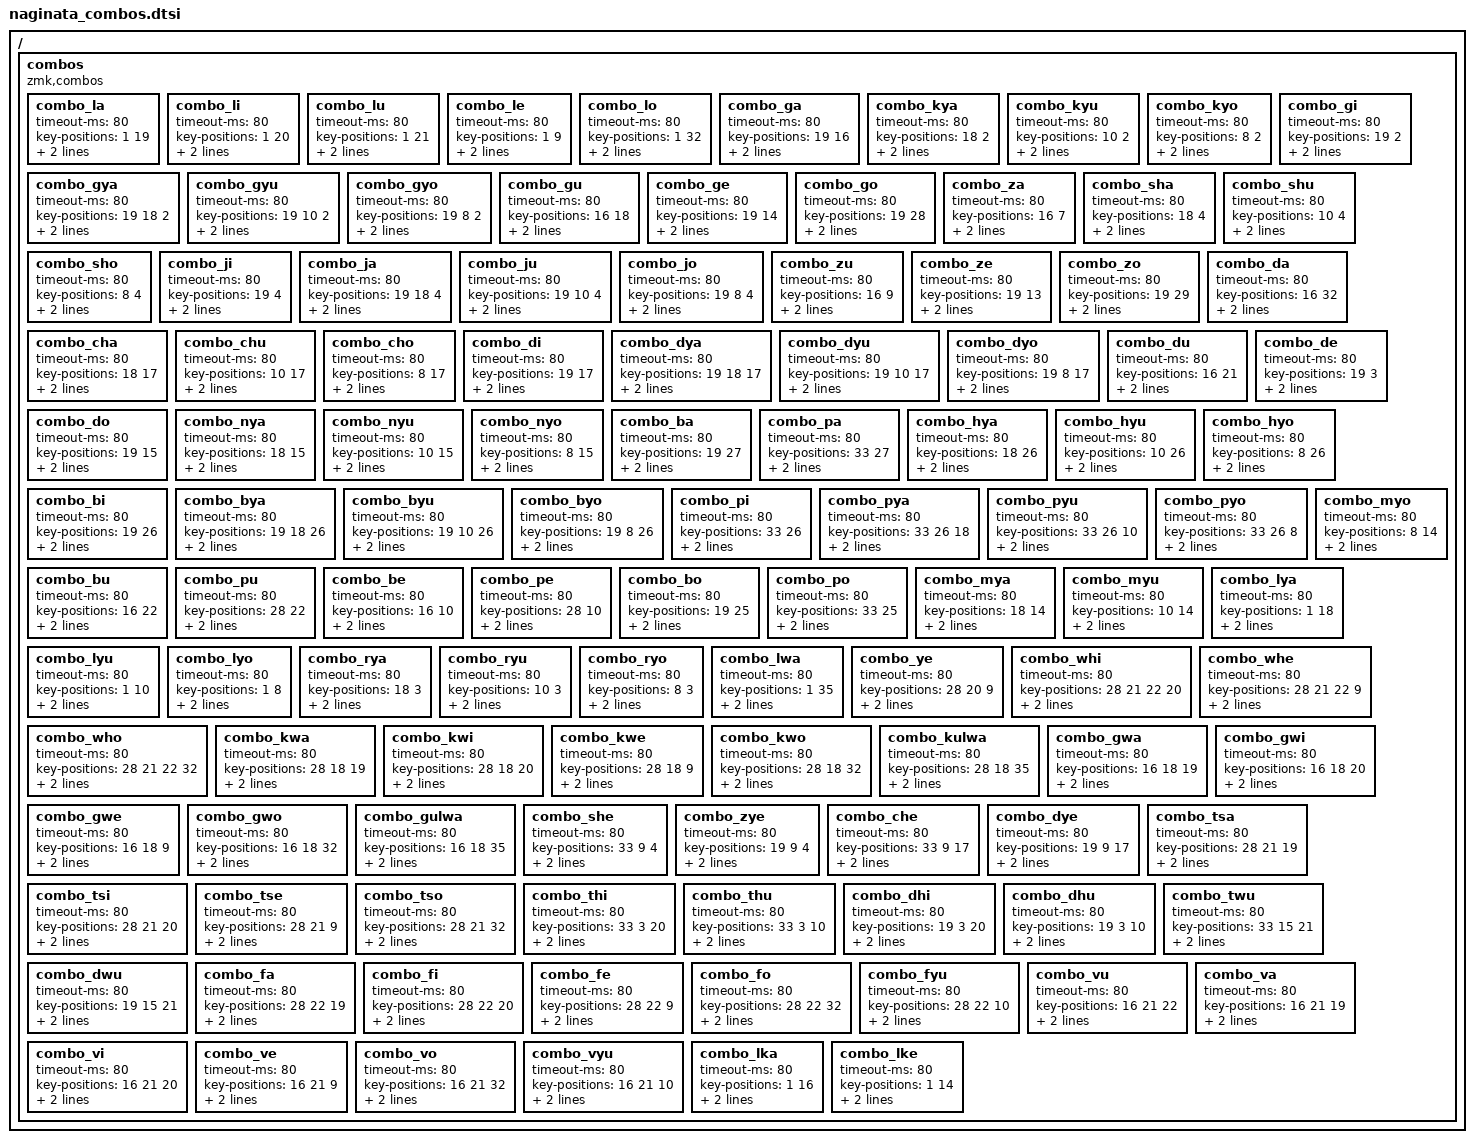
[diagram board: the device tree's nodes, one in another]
/*
 * Copyright (c) 2020 The ZMK Contributors
 *
 * SPDX-License-Identifier: MIT
 */

#pragma once

#include "layers.h"

/ {
    combos {
        compatible = "zmk,combos";

        combo_la { // ぁ
            timeout-ms = <80>;
            key-positions = <1 19>;
            bindings = <&kana_la>;
            layers = <LAYER_NAGINATA LAYER_NAGINATA_EXT>;
        };

        combo_li { // ぃ
            timeout-ms = <80>;
            key-positions = <1 20>;
            bindings = <&kana_li>;
            layers = <LAYER_NAGINATA LAYER_NAGINATA_EXT>;
        };

        combo_lu { // ぅ
            timeout-ms = <80>;
            key-positions = <1 21>;
            bindings = <&kana_lu>;
            layers = <LAYER_NAGINATA LAYER_NAGINATA_EXT>;
        };

        combo_le { // ぇ
            timeout-ms = <80>;
            key-positions = <1 9>;
            bindings = <&kana_le>;
            layers = <LAYER_NAGINATA LAYER_NAGINATA_EXT>;
        };

        combo_lo { // ぉ
            timeout-ms = <80>;
            key-positions = <1 32>;
            bindings = <&kana_lo>;
            layers = <LAYER_NAGINATA LAYER_NAGINATA_EXT>;
        };

        combo_ga { // が
            timeout-ms = <80>;
            key-positions = <19 16>;
            bindings = <&kana_ga>;
            layers = <LAYER_NAGINATA LAYER_NAGINATA_EXT>;
        };

        combo_kya { // きゃ
            timeout-ms = <80>;
            key-positions = <18 2>;
            bindings = <&kana_kya>;
            layers = <LAYER_NAGINATA LAYER_NAGINATA_EXT>;
        };

        combo_kyu { // きゅ
            timeout-ms = <80>;
            key-positions = <10 2>;
            bindings = <&kana_kyu>;
            layers = <LAYER_NAGINATA LAYER_NAGINATA_EXT>;
        };

        combo_kyo { // きょ
            timeout-ms = <80>;
            key-positions = <8 2>;
            bindings = <&kana_kyo>;
            layers = <LAYER_NAGINATA LAYER_NAGINATA_EXT>;
        };

        combo_gi { // ぎ
            timeout-ms = <80>;
            key-positions = <19 2>;
            bindings = <&kana_gi>;
            layers = <LAYER_NAGINATA LAYER_NAGINATA_EXT>;
        };

        combo_gya { // ぎゃ
            timeout-ms = <80>;
            key-positions = <19 18 2>;
            bindings = <&kana_gya>;
            layers = <LAYER_NAGINATA LAYER_NAGINATA_EXT>;
        };

        combo_gyu { // ぎゅ
            timeout-ms = <80>;
            key-positions = <19 10 2>;
            bindings = <&kana_gyu>;
            layers = <LAYER_NAGINATA LAYER_NAGINATA_EXT>;
        };

        combo_gyo { // ぎょ
            timeout-ms = <80>;
            key-positions = <19 8 2>;
            bindings = <&kana_gyo>;
            layers = <LAYER_NAGINATA LAYER_NAGINATA_EXT>;
        };

        combo_gu { // ぐ
            timeout-ms = <80>;
            key-positions = <16 18>;
            bindings = <&kana_gu>;
            layers = <LAYER_NAGINATA LAYER_NAGINATA_EXT>;
        };

        combo_ge { // げ
            timeout-ms = <80>;
            key-positions = <19 14>;
            bindings = <&kana_ge>;
            layers = <LAYER_NAGINATA LAYER_NAGINATA_EXT>;
        };

        combo_go { // ご
            timeout-ms = <80>;
            key-positions = <19 28>;
            bindings = <&kana_go>;
            layers = <LAYER_NAGINATA LAYER_NAGINATA_EXT>;
        };

        combo_za { // ざ
            timeout-ms = <80>;
            key-positions = <16 7>;
            bindings = <&kana_za>;
            layers = <LAYER_NAGINATA LAYER_NAGINATA_EXT>;
        };

        combo_sha { // しゃ
            timeout-ms = <80>;
            key-positions = <18 4>;
            bindings = <&kana_sha>;
            layers = <LAYER_NAGINATA LAYER_NAGINATA_EXT>;
        };

        combo_shu { // しゅ
            timeout-ms = <80>;
            key-positions = <10 4>;
            bindings = <&kana_shu>;
            layers = <LAYER_NAGINATA LAYER_NAGINATA_EXT>;
        };

        combo_sho { // しょ
            timeout-ms = <80>;
            key-positions = <8 4>;
            bindings = <&kana_sho>;
            layers = <LAYER_NAGINATA LAYER_NAGINATA_EXT>;
        };

        combo_ji { // じ
            timeout-ms = <80>;
            key-positions = <19 4>;
            bindings = <&kana_ji>;
            layers = <LAYER_NAGINATA LAYER_NAGINATA_EXT>;
        };

        combo_ja { // じゃ
            timeout-ms = <80>;
            key-positions = <19 18 4>;
            bindings = <&kana_ja>;
            layers = <LAYER_NAGINATA LAYER_NAGINATA_EXT>;
        };

        combo_ju { // じゅ
            timeout-ms = <80>;
            key-positions = <19 10 4>;
            bindings = <&kana_ju>;
            layers = <LAYER_NAGINATA LAYER_NAGINATA_EXT>;
        };

        combo_jo { // じょ
            timeout-ms = <80>;
            key-positions = <19 8 4>;
            bindings = <&kana_jo>;
            layers = <LAYER_NAGINATA LAYER_NAGINATA_EXT>;
        };

        combo_zu { // ず
            timeout-ms = <80>;
            key-positions = <16 9>;
            bindings = <&kana_zu>;
            layers = <LAYER_NAGINATA LAYER_NAGINATA_EXT>;
        };

        combo_ze { // ぜ
            timeout-ms = <80>;
            key-positions = <19 13>;
            bindings = <&kana_ze>;
            layers = <LAYER_NAGINATA LAYER_NAGINATA_EXT>;
        };

        combo_zo { // ぞ
            timeout-ms = <80>;
            key-positions = <19 29>;
            bindings = <&kana_zo>;
            layers = <LAYER_NAGINATA LAYER_NAGINATA_EXT>;
        };

        combo_da { // だ
            timeout-ms = <80>;
            key-positions = <16 32>;
            bindings = <&kana_da>;
            layers = <LAYER_NAGINATA LAYER_NAGINATA_EXT>;
        };

        combo_cha { // ちゃ
            timeout-ms = <80>;
            key-positions = <18 17>;
            bindings = <&kana_cha>;
            layers = <LAYER_NAGINATA LAYER_NAGINATA_EXT>;
        };

        combo_chu { // ちゅ
            timeout-ms = <80>;
            key-positions = <10 17>;
            bindings = <&kana_chu>;
            layers = <LAYER_NAGINATA LAYER_NAGINATA_EXT>;
        };

        combo_cho { // ちょ
            timeout-ms = <80>;
            key-positions = <8 17>;
            bindings = <&kana_cho>;
            layers = <LAYER_NAGINATA LAYER_NAGINATA_EXT>;
        };

        combo_di { // ぢ
            timeout-ms = <80>;
            key-positions = <19 17>;
            bindings = <&kana_di>;
            layers = <LAYER_NAGINATA LAYER_NAGINATA_EXT>;
        };

        combo_dya { // ぢゃ
            timeout-ms = <80>;
            key-positions = <19 18 17>;
            bindings = <&kana_dya>;
            layers = <LAYER_NAGINATA LAYER_NAGINATA_EXT>;
        };

        combo_dyu { // ぢゅ
            timeout-ms = <80>;
            key-positions = <19 10 17>;
            bindings = <&kana_dyu>;
            layers = <LAYER_NAGINATA LAYER_NAGINATA_EXT>;
        };

        combo_dyo { // ぢょ
            timeout-ms = <80>;
            key-positions = <19 8 17>;
            bindings = <&kana_dyo>;
            layers = <LAYER_NAGINATA LAYER_NAGINATA_EXT>;
        };

        combo_du { // づ
            timeout-ms = <80>;
            key-positions = <16 21>;
            bindings = <&kana_du>;
            layers = <LAYER_NAGINATA LAYER_NAGINATA_EXT>;
        };

        combo_de { // で
            timeout-ms = <80>;
            key-positions = <19 3>;
            bindings = <&kana_de>;
            layers = <LAYER_NAGINATA LAYER_NAGINATA_EXT>;
        };

        combo_do { // ど
            timeout-ms = <80>;
            key-positions = <19 15>;
            bindings = <&kana_do>;
            layers = <LAYER_NAGINATA LAYER_NAGINATA_EXT>;
        };

        combo_nya { // にゃ
            timeout-ms = <80>;
            key-positions = <18 15>;
            bindings = <&kana_nya>;
            layers = <LAYER_NAGINATA LAYER_NAGINATA_EXT>;
        };

        combo_nyu { // にゅ
            timeout-ms = <80>;
            key-positions = <10 15>;
            bindings = <&kana_nyu>;
            layers = <LAYER_NAGINATA LAYER_NAGINATA_EXT>;
        };

        combo_nyo { // にょ
            timeout-ms = <80>;
            key-positions = <8 15>;
            bindings = <&kana_nyo>;
            layers = <LAYER_NAGINATA LAYER_NAGINATA_EXT>;
        };

        combo_ba { // ば
            timeout-ms = <80>;
            key-positions = <19 27>;
            bindings = <&kana_ba>;
            layers = <LAYER_NAGINATA LAYER_NAGINATA_EXT>;
        };

        combo_pa { // ぱ
            timeout-ms = <80>;
            key-positions = <33 27>;
            bindings = <&kana_pa>;
            layers = <LAYER_NAGINATA LAYER_NAGINATA_EXT>;
        };

        combo_hya { // ひゃ
            timeout-ms = <80>;
            key-positions = <18 26>;
            bindings = <&kana_hya>;
            layers = <LAYER_NAGINATA LAYER_NAGINATA_EXT>;
        };

        combo_hyu { // ひゅ
            timeout-ms = <80>;
            key-positions = <10 26>;
            bindings = <&kana_hyu>;
            layers = <LAYER_NAGINATA LAYER_NAGINATA_EXT>;
        };

        combo_hyo { // ひょ
            timeout-ms = <80>;
            key-positions = <8 26>;
            bindings = <&kana_hyo>;
            layers = <LAYER_NAGINATA LAYER_NAGINATA_EXT>;
        };

        combo_bi { // び
            timeout-ms = <80>;
            key-positions = <19 26>;
            bindings = <&kana_bi>;
            layers = <LAYER_NAGINATA LAYER_NAGINATA_EXT>;
        };

        combo_bya { // びゃ
            timeout-ms = <80>;
            key-positions = <19 18 26>;
            bindings = <&kana_bya>;
            layers = <LAYER_NAGINATA LAYER_NAGINATA_EXT>;
        };

        combo_byu { // びゅ
            timeout-ms = <80>;
            key-positions = <19 10 26>;
            bindings = <&kana_byu>;
            layers = <LAYER_NAGINATA LAYER_NAGINATA_EXT>;
        };

        combo_byo { // びょ
            timeout-ms = <80>;
            key-positions = <19 8 26>;
            bindings = <&kana_byo>;
            layers = <LAYER_NAGINATA LAYER_NAGINATA_EXT>;
        };

        combo_pi { // ぴ
            timeout-ms = <80>;
            key-positions = <33 26>;
            bindings = <&kana_pi>;
            layers = <LAYER_NAGINATA LAYER_NAGINATA_EXT>;
        };

        combo_pya { // ぴゃ
            timeout-ms = <80>;
            key-positions = <33 26 18>;
            bindings = <&kana_pya>;
            layers = <LAYER_NAGINATA LAYER_NAGINATA_EXT>;
        };

        combo_pyu { // ぴゅ
            timeout-ms = <80>;
            key-positions = <33 26 10>;
            bindings = <&kana_pyu>;
            layers = <LAYER_NAGINATA LAYER_NAGINATA_EXT>;
        };

        combo_pyo { // ぴょ
            timeout-ms = <80>;
            key-positions = <33 26 8>;
            bindings = <&kana_pyo>;
            layers = <LAYER_NAGINATA LAYER_NAGINATA_EXT>;
        };

        combo_bu { // ぶ
            timeout-ms = <80>;
            key-positions = <16 22>;
            bindings = <&kana_bu>;
            layers = <LAYER_NAGINATA LAYER_NAGINATA_EXT>;
        };

        combo_pu { // ぷ
            timeout-ms = <80>;
            key-positions = <28 22>;
            bindings = <&kana_pu>;
            layers = <LAYER_NAGINATA LAYER_NAGINATA_EXT>;
        };

        combo_be { // べ
            timeout-ms = <80>;
            key-positions = <16 10>;
            bindings = <&kana_be>;
            layers = <LAYER_NAGINATA LAYER_NAGINATA_EXT>;
        };

        combo_pe { // ぺ
            timeout-ms = <80>;
            key-positions = <28 10>;
            bindings = <&kana_pe>;
            layers = <LAYER_NAGINATA LAYER_NAGINATA_EXT>;
        };

        combo_bo { // ぼ
            timeout-ms = <80>;
            key-positions = <19 25>;
            bindings = <&kana_bo>;
            layers = <LAYER_NAGINATA LAYER_NAGINATA_EXT>;
        };

        combo_po { // ぽ
            timeout-ms = <80>;
            key-positions = <33 25>;
            bindings = <&kana_po>;
            layers = <LAYER_NAGINATA LAYER_NAGINATA_EXT>;
        };

        combo_mya { // みゃ
            timeout-ms = <80>;
            key-positions = <18 14>;
            bindings = <&kana_mya>;
            layers = <LAYER_NAGINATA LAYER_NAGINATA_EXT>;
        };

        combo_myu { // みゅ
            timeout-ms = <80>;
            key-positions = <10 14>;
            bindings = <&kana_myu>;
            layers = <LAYER_NAGINATA LAYER_NAGINATA_EXT>;
        };

        combo_myo { // みょ
            timeout-ms = <80>;
            key-positions = <8 14>;
            bindings = <&kana_myo>;
            layers = <LAYER_NAGINATA LAYER_NAGINATA_EXT>;
        };

        combo_lya { // ゃ
            timeout-ms = <80>;
            key-positions = <1 18>;
            bindings = <&kana_lya>;
            layers = <LAYER_NAGINATA LAYER_NAGINATA_EXT>;
        };

        combo_lyu { // ゅ
            timeout-ms = <80>;
            key-positions = <1 10>;
            bindings = <&kana_lyu>;
            layers = <LAYER_NAGINATA LAYER_NAGINATA_EXT>;
        };

        combo_lyo { // ょ
            timeout-ms = <80>;
            key-positions = <1 8>;
            bindings = <&kana_lyo>;
            layers = <LAYER_NAGINATA LAYER_NAGINATA_EXT>;
        };

        combo_rya { // りゃ
            timeout-ms = <80>;
            key-positions = <18 3>;
            bindings = <&kana_rya>;
            layers = <LAYER_NAGINATA LAYER_NAGINATA_EXT>;
        };

        combo_ryu { // りゅ
            timeout-ms = <80>;
            key-positions = <10 3>;
            bindings = <&kana_ryu>;
            layers = <LAYER_NAGINATA LAYER_NAGINATA_EXT>;
        };

        combo_ryo { // りょ
            timeout-ms = <80>;
            key-positions = <8 3>;
            bindings = <&kana_ryo>;
            layers = <LAYER_NAGINATA LAYER_NAGINATA_EXT>;
        };

        combo_lwa { // ゎ
            timeout-ms = <80>;
            key-positions = <1 35>;
            bindings = <&kana_lwa>;
            layers = <LAYER_NAGINATA LAYER_NAGINATA_EXT>;
        };

        combo_ye { // イェ
            timeout-ms = <80>;
            key-positions = <28 20 9>;
            bindings = <&kana_ye>;
            layers = <LAYER_NAGINATA LAYER_NAGINATA_EXT>;
        };

        combo_whi { // ウィ
            timeout-ms = <80>;
            key-positions = <28 21 22 20>;
            bindings = <&kana_whi>;
            layers = <LAYER_NAGINATA LAYER_NAGINATA_EXT>;
        };

        combo_whe { // ウェ
            timeout-ms = <80>;
            key-positions = <28 21 22 9>;
            bindings = <&kana_whe>;
            layers = <LAYER_NAGINATA LAYER_NAGINATA_EXT>;
        };

        combo_who { // ウォ
            timeout-ms = <80>;
            key-positions = <28 21 22 32>;
            bindings = <&kana_who>;
            layers = <LAYER_NAGINATA LAYER_NAGINATA_EXT>;
        };

        combo_kwa { // クァ
            timeout-ms = <80>;
            key-positions = <28 18 19>;
            bindings = <&kana_kwa>;
            layers = <LAYER_NAGINATA LAYER_NAGINATA_EXT>;
        };

        combo_kwi { // クィ
            timeout-ms = <80>;
            key-positions = <28 18 20>;
            bindings = <&kana_kwi>;
            layers = <LAYER_NAGINATA LAYER_NAGINATA_EXT>;
        };

        combo_kwe { // クェ
            timeout-ms = <80>;
            key-positions = <28 18 9>;
            bindings = <&kana_kwe>;
            layers = <LAYER_NAGINATA LAYER_NAGINATA_EXT>;
        };

        combo_kwo { // クォ
            timeout-ms = <80>;
            key-positions = <28 18 32>;
            bindings = <&kana_kwo>;
            layers = <LAYER_NAGINATA LAYER_NAGINATA_EXT>;
        };

        combo_kulwa { // クヮ
            timeout-ms = <80>;
            key-positions = <28 18 35>;
            bindings = <&kana_kulwa>;
            layers = <LAYER_NAGINATA LAYER_NAGINATA_EXT>;
        };

        combo_gwa { // グァ
            timeout-ms = <80>;
            key-positions = <16 18 19>;
            bindings = <&kana_gwa>;
            layers = <LAYER_NAGINATA LAYER_NAGINATA_EXT>;
        };

        combo_gwi { // グィ
            timeout-ms = <80>;
            key-positions = <16 18 20>;
            bindings = <&kana_gwi>;
            layers = <LAYER_NAGINATA LAYER_NAGINATA_EXT>;
        };

        combo_gwe { // グェ
            timeout-ms = <80>;
            key-positions = <16 18 9>;
            bindings = <&kana_gwe>;
            layers = <LAYER_NAGINATA LAYER_NAGINATA_EXT>;
        };

        combo_gwo { // グォ
            timeout-ms = <80>;
            key-positions = <16 18 32>;
            bindings = <&kana_gwo>;
            layers = <LAYER_NAGINATA LAYER_NAGINATA_EXT>;
        };

        combo_gulwa { // グヮ
            timeout-ms = <80>;
            key-positions = <16 18 35>;
            bindings = <&kana_gulwa>;
            layers = <LAYER_NAGINATA LAYER_NAGINATA_EXT>;
        };

        combo_she { // シェ
            timeout-ms = <80>;
            key-positions = <33 9 4>;
            bindings = <&kana_she>;
            layers = <LAYER_NAGINATA LAYER_NAGINATA_EXT>;
        };

        combo_zye { // ジェ
            timeout-ms = <80>;
            key-positions = <19 9 4>;
            bindings = <&kana_zye>;
            layers = <LAYER_NAGINATA LAYER_NAGINATA_EXT>;
        };

        combo_che { // チェ
            timeout-ms = <80>;
            key-positions = <33 9 17>;
            bindings = <&kana_che>;
            layers = <LAYER_NAGINATA LAYER_NAGINATA_EXT>;
        };

        combo_dye { // ヂェ
            timeout-ms = <80>;
            key-positions = <19 9 17>;
            bindings = <&kana_dye>;
            layers = <LAYER_NAGINATA LAYER_NAGINATA_EXT>;
        };

        combo_tsa { // ツァ
            timeout-ms = <80>;
            key-positions = <28 21 19>;
            bindings = <&kana_tsa>;
            layers = <LAYER_NAGINATA LAYER_NAGINATA_EXT>;
        };

        combo_tsi { // ツィ
            timeout-ms = <80>;
            key-positions = <28 21 20>;
            bindings = <&kana_tsi>;
            layers = <LAYER_NAGINATA LAYER_NAGINATA_EXT>;
        };

        combo_tse { // ツェ
            timeout-ms = <80>;
            key-positions = <28 21 9>;
            bindings = <&kana_tse>;
            layers = <LAYER_NAGINATA LAYER_NAGINATA_EXT>;
        };

        combo_tso { // ツォ
            timeout-ms = <80>;
            key-positions = <28 21 32>;
            bindings = <&kana_tso>;
            layers = <LAYER_NAGINATA LAYER_NAGINATA_EXT>;
        };

        combo_thi { // ティ
            timeout-ms = <80>;
            key-positions = <33 3 20>;
            bindings = <&kana_thi>;
            layers = <LAYER_NAGINATA LAYER_NAGINATA_EXT>;
        };

        combo_thu { // テュ
            timeout-ms = <80>;
            key-positions = <33 3 10>;
            bindings = <&kana_thu>;
            layers = <LAYER_NAGINATA LAYER_NAGINATA_EXT>;
        };

        combo_dhi { // ディ
            timeout-ms = <80>;
            key-positions = <19 3 20>;
            bindings = <&kana_dhi>;
            layers = <LAYER_NAGINATA LAYER_NAGINATA_EXT>;
        };

        combo_dhu { // デュ
            timeout-ms = <80>;
            key-positions = <19 3 10>;
            bindings = <&kana_dhu>;
            layers = <LAYER_NAGINATA LAYER_NAGINATA_EXT>;
        };

        combo_twu { // トゥ
            timeout-ms = <80>;
            key-positions = <33 15 21>;
            bindings = <&kana_twu>;
            layers = <LAYER_NAGINATA LAYER_NAGINATA_EXT>;
        };

        combo_dwu { // ドゥ
            timeout-ms = <80>;
            key-positions = <19 15 21>;
            bindings = <&kana_dwu>;
            layers = <LAYER_NAGINATA LAYER_NAGINATA_EXT>;
        };

        combo_fa { // ファ
            timeout-ms = <80>;
            key-positions = <28 22 19>;
            bindings = <&kana_fa>;
            layers = <LAYER_NAGINATA LAYER_NAGINATA_EXT>;
        };

        combo_fi { // フィ
            timeout-ms = <80>;
            key-positions = <28 22 20>;
            bindings = <&kana_fi>;
            layers = <LAYER_NAGINATA LAYER_NAGINATA_EXT>;
        };

        combo_fe { // フェ
            timeout-ms = <80>;
            key-positions = <28 22 9>;
            bindings = <&kana_fe>;
            layers = <LAYER_NAGINATA LAYER_NAGINATA_EXT>;
        };

        combo_fo { // フォ
            timeout-ms = <80>;
            key-positions = <28 22 32>;
            bindings = <&kana_fo>;
            layers = <LAYER_NAGINATA LAYER_NAGINATA_EXT>;
        };

        combo_fyu { // フュ
            timeout-ms = <80>;
            key-positions = <28 22 10>;
            bindings = <&kana_fyu>;
            layers = <LAYER_NAGINATA LAYER_NAGINATA_EXT>;
        };

        combo_vu { // ヴ
            timeout-ms = <80>;
            key-positions = <16 21 22>;
            bindings = <&kana_vu>;
            layers = <LAYER_NAGINATA LAYER_NAGINATA_EXT>;
        };

        combo_va { // ヴァ
            timeout-ms = <80>;
            key-positions = <16 21 19>;
            bindings = <&kana_va>;
            layers = <LAYER_NAGINATA LAYER_NAGINATA_EXT>;
        };

        combo_vi { // ヴィ
            timeout-ms = <80>;
            key-positions = <16 21 20>;
            bindings = <&kana_vi>;
            layers = <LAYER_NAGINATA LAYER_NAGINATA_EXT>;
        };

        combo_ve { // ヴェ
            timeout-ms = <80>;
            key-positions = <16 21 9>;
            bindings = <&kana_ve>;
            layers = <LAYER_NAGINATA LAYER_NAGINATA_EXT>;
        };

        combo_vo { // ヴォ
            timeout-ms = <80>;
            key-positions = <16 21 32>;
            bindings = <&kana_vo>;
            layers = <LAYER_NAGINATA LAYER_NAGINATA_EXT>;
        };

        combo_vyu { // ヴュ
            timeout-ms = <80>;
            key-positions = <16 21 10>;
            bindings = <&kana_vyu>;
            layers = <LAYER_NAGINATA LAYER_NAGINATA_EXT>;
        };

        combo_lka { // ヵ
            timeout-ms = <80>;
            key-positions = <1 16>;
            bindings = <&kana_lka>;
            layers = <LAYER_NAGINATA LAYER_NAGINATA_EXT>;
        };

        combo_lke { // ヶ
            timeout-ms = <80>;
            key-positions = <1 14>;
            bindings = <&kana_lke>;
            layers = <LAYER_NAGINATA LAYER_NAGINATA_EXT>;
        };
    };
};

